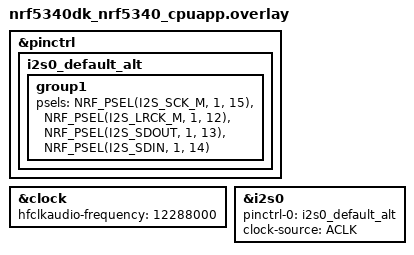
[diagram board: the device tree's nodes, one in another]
/*
 * Copyright (c) 2023 Nordic Semiconductor ASA
 *
 * SPDX-License-Identifier: Apache-2.0
 */

#include "../app.overlay"

&pinctrl {
	i2s0_default_alt: i2s0_default_alt {
		group1 {
			psels = <NRF_PSEL(I2S_SCK_M, 1, 15)>,
				<NRF_PSEL(I2S_LRCK_M, 1, 12)>,
				<NRF_PSEL(I2S_SDOUT, 1, 13)>,
				<NRF_PSEL(I2S_SDIN, 1, 14)>;
		};
	};
};

&clock {
	hfclkaudio-frequency = <12288000>;
};

i2s_rxtx: &i2s0 {
	status = "okay";
	pinctrl-0 = <&i2s0_default_alt>;
	pinctrl-names = "default";
	clock-source = "ACLK";
};
